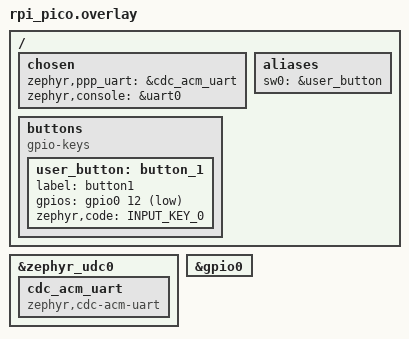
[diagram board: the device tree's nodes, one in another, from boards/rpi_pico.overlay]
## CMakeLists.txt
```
# SPDX-License-Identifier: Apache-2.0

cmake_minimum_required(VERSION 3.20.0)

find_package(Zephyr REQUIRED HINTS $ENV{ZEPHYR_BASE})
project(PanduzaHA-ng)

set(app_sources
    src/main.c
    src/app_mqtt.c
    src/panduza.c
    src/panduza_dio.c
)
target_sources(app PRIVATE ${app_sources})
```

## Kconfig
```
# Config options for mqtt_publisher sample application

# Copyright (c) 2020 Intel Corporation
# SPDX-License-Identifier: Apache-2.0

mainmenu "PanduzaHA-ng application"

config NET_SAMPLE_APP_MAX_ITERATIONS
	int "Number of times to Publish sample MQTT messages"
	default 500
	help
	  Send sample MQTT messages this many times in a MQTT connection
	  before exiting. A value of zero means that the messages are sent
	  forever.

config NET_SAMPLE_APP_MAX_CONNECTIONS
	int "Number of times to connect to the MQTT server"
	default 0
	help
	  Number of times to connect to the MQTT server. With each connection
	  send NET_SAMPLE_APP_MAX_ITERATIONS amount of MQTT sample messages.
	  A value of zero means to continue forever.

menu "Panduza configuration"

config PANDUZA_BENCH_NAME
	string "Bench Name"
	default "default"
	help
		"Change bench name that appear on the broker" 

config PANDUZA_DEVICE_NAME
	string "Device Name"
	default BOARD
	help
		"Change the device name that appear on the broker" 


endmenu

menu "Zephy Kernel"
source "Kconfig.zephyr"
endmenu
```

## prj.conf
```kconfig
CONFIG_UART_INTERRUPT_DRIVEN=y
# CONFIG_NET_IPV6 is not set
CONFIG_PINCTRL=y
CONFIG_GPIO=y
CONFIG_SERIAL=y
# CONFIG_NET_TCP_CHECKSUM is not set
CONFIG_NET_DRIVERS=y
CONFIG_CONSOLE=y
CONFIG_UART_CONSOLE=y
CONFIG_NET_PPP=y
CONFIG_PPP_CLIENT_CLIENTSERVER=y
# CONFIG_MODEM_MODULES=y
# CONFIG_MODEM_PPP=y
CONFIG_NETWORKING=y
CONFIG_NET_L2_PPP=y
CONFIG_NET_IPV4=y
CONFIG_NET_TCP=y
# CONFIG_NET_TCP_RANDOMIZED_RTO is not set
# CONFIG_NET_TCP_FAST_RETRANSMIT is not set
# CONFIG_NET_TCP_CONGESTION_AVOIDANCE is not set
# CONFIG_NET_TCP_ISN_RFC6528 is not set
# CONFIG_NET_TCP_REJECT_CONN_WITH_RST is not set
# CONFIG_NET_UDP is not set
# CONFIG_NET_LOG=y
CONFIG_MQTT_LIB=y
CONFIG_TEST_RANDOM_GENERATOR=y

CONFIG_NET_CONFIG_SETTINGS=y
CONFIG_NET_CONFIG_MY_IPV4_ADDR="192.0.1.1"
CONFIG_NET_CONFIG_PEER_IPV4_ADDR="192.0.1.2"

CONFIG_JSON_LIBRARY=y
CONFIG_GPIO_GET_CONFIG=y
CONFIG_LOG=y
CONFIG_LOG_MODE_MINIMAL=y
```

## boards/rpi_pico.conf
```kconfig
CONFIG_USB_DEVICE_STACK=y
CONFIG_USB_DEVICE_INITIALIZE_AT_BOOT=y
CONFIG_CDC_ACM_DTE_RATE_CALLBACK_SUPPORT=y
```

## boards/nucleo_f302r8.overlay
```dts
/*
 * Copyright (c) 2021 Nordic Semiconductor ASA
 * SPDX-License-Identifier: Apache-2.0
 */

/* This devicetree overlay file will be automatically picked by the Zephyr
 * build system when building the sample for the nucleo_f302r8 board. It shows
 * how the example-application can be built on sample boards already provided
 * by Zephyr.
 */

/ {
	chosen {
		zephyr,uart_pipe=&uart0;
	};
};

&gpioc {
	status = "okay";
};
```

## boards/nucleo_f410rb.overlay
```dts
/*
 * Copyright (c) 2021 Nordic Semiconductor ASA
 * SPDX-License-Identifier: Apache-2.0
 */

/ {
    chosen {
        zephyr,ppp_uart=&usart2;
        zephyr,console = &usart1;
    };

    pza_dio: panduza-dio {
        compatible = "panduza,dios";
        #gpio-cells = <2>;
        pza-gpios = <&gpioa 5 GPIO_ACTIVE_HIGH>,
                    <&gpioc 13 GPIO_ACTIVE_LOW>;
    };
};
```

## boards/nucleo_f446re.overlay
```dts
/*
 * Copyright (c) 2021 Nordic Semiconductor ASA
 * SPDX-License-Identifier: Apache-2.0
 */

/* This devicetree overlay file will be automatically picked by the Zephyr
 * build system when building the sample for the nucleo_f302r8 board. It shows
 * how the example-application can be built on sample boards already provided
 * by Zephyr.
 */

/ {
	chosen {
		zephyr,ppp_uart=&usart2;
		zephyr,console = &usart1;
	};
};

&gpioc {
	status = "okay";
};
```

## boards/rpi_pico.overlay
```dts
#include <zephyr/dt-bindings/input/input-event-codes.h>

/ {
	chosen {
		zephyr,ppp_uart=&cdc_acm_uart;
		zephyr,console = &uart0;
	};

	buttons {
		compatible = "gpio-keys";
		user_button: button_1 {
			label = "button1";
			gpios = <&gpio0 12 (GPIO_PULL_UP | GPIO_ACTIVE_LOW)>;
			zephyr,code = <INPUT_KEY_0>;
		};
	};

	aliases {
		sw0 = &user_button;
	};
};

&zephyr_udc0 {
	cdc_acm_uart: cdc_acm_uart {
		compatible = "zephyr,cdc-acm-uart";
	};
};

&gpio0 {
	status = "okay";
};
```

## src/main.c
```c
/*
 * Copyright (c) 2017 Intel Corporation
 *
 * SPDX-License-Identifier: Apache-2.0
 */

#include <zephyr/logging/log.h>
LOG_MODULE_REGISTER(panduzaHA_standalone, LOG_LEVEL_DBG);

#include <zephyr/kernel.h>

#include <zephyr/random/random.h>

#include <string.h>
#include <errno.h>

#include "config.h"
#include "panduza.h"
#include "app_mqtt.h"
#include "panduza_dio.h"

static int start_app(void)
{
	int r = 0, i = 0;

	while (!CONFIG_NET_SAMPLE_APP_MAX_CONNECTIONS ||
	       i++ < CONFIG_NET_SAMPLE_APP_MAX_CONNECTIONS) {
		r = publisher();

		if (!CONFIG_NET_SAMPLE_APP_MAX_CONNECTIONS) {
			k_sleep(K_MSEC(5000));
		}
	}

	return r;
}

#if defined(CONFIG_USERSPACE)
#define STACK_SIZE 2048

#if defined(CONFIG_NET_TC_THREAD_COOPERATIVE)
#define THREAD_PRIORITY K_PRIO_COOP(CONFIG_NUM_COOP_PRIORITIES - 1)
#else
#define THREAD_PRIORITY K_PRIO_PREEMPT(8)
#endif

K_THREAD_DEFINE(app_thread, STACK_SIZE,
		start_app, NULL, NULL, NULL,
		THREAD_PRIORITY, K_USER, -1);

static K_HEAP_DEFINE(app_mem_pool, 1024 * 2);
#endif

int main(void)
{
	pza_dio_init();

#if defined(CONFIG_MQTT_LIB_TLS)
	int rc;

	rc = tls_init();
	PRINT_RESULT("tls_init", rc);
#endif

#if defined(CONFIG_USERSPACE)
	int ret;

	struct k_mem_partition *parts[] = {
#if Z_LIBC_PARTITION_EXISTS
		&z_libc_partition,
#endif
		&app_partition
	};

	ret = k_mem_domain_init(&app_domain, ARRAY_SIZE(parts), parts);
	__ASSERT(ret == 0, "k_mem_domain_init() failed %d", ret);
	ARG_UNUSED(ret);

	k_mem_domain_add_thread(&app_domain, app_thread);
	k_thread_heap_assign(app_thread, &app_mem_pool);

	k_thread_start(app_thread);
	k_thread_join(app_thread, K_FOREVER);
#else
	exit(start_app());
#endif
	return 0;
}
```

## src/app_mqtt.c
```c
#include <zephyr/net/mqtt.h>
#include <zephyr/random/random.h>
#include <zephyr/data/json.h>
#include "panduza.h"

#include "app_mqtt.h"

#include <zephyr/logging/log.h>
LOG_MODULE_REGISTER(app_mqtt, LOG_LEVEL_DBG);

#if defined(CONFIG_USERSPACE)
#include <zephyr/app_memory/app_memdomain.h>
K_APPMEM_PARTITION_DEFINE(app_partition);
struct k_mem_domain app_domain;
#define APP_BMEM K_APP_BMEM(app_partition)
#define APP_DMEM K_APP_DMEM(app_partition)
#else
#define APP_BMEM
#define APP_DMEM
#endif

APP_BMEM app_mqtt_t app;

#if defined(CONFIG_MQTT_LIB_WEBSOCKET)
/* Making RX buffer large enough that the full IPv6 packet can fit into it */
#define MQTT_LIB_WEBSOCKET_RECV_BUF_LEN 1280

/* Websocket needs temporary buffer to store partial packets */
static APP_BMEM uint8_t temp_ws_rx_buf[MQTT_LIB_WEBSOCKET_RECV_BUF_LEN];
#endif

#if defined(CONFIG_SOCKS)
static APP_BMEM struct sockaddr socks5_proxy;
#endif

static void broker_init(struct sockaddr_storage *broker)
{
#if defined(CONFIG_NET_IPV6)
	struct sockaddr_in6 *broker6 = (struct sockaddr_in6 *)&broker;

	broker6->sin6_family = AF_INET6;
	broker6->sin6_port = htons(SERVER_PORT);
	zsock_inet_pton(AF_INET6, SERVER_ADDR, &broker6->sin6_addr);

#if defined(CONFIG_SOCKS)
	struct sockaddr_in6 *proxy6 = (struct sockaddr_in6 *)&socks5_proxy;

	proxy6->sin6_family = AF_INET6;
	proxy6->sin6_port = htons(SOCKS5_PROXY_PORT);
	zsock_inet_pton(AF_INET6, SOCKS5_PROXY_ADDR, &proxy6->sin6_addr);
#endif
#else
	struct sockaddr_in *broker4 = (struct sockaddr_in *)broker;

	broker4->sin_family = AF_INET;
	broker4->sin_port = htons(SERVER_PORT);
	zsock_inet_pton(AF_INET, SERVER_ADDR, &broker4->sin_addr);
#if defined(CONFIG_SOCKS)
	struct sockaddr_in *proxy4 = (struct sockaddr_in *)&socks5_proxy;

	proxy4->sin_family = AF_INET;
	proxy4->sin_port = htons(SOCKS5_PROXY_PORT);
	zsock_inet_pton(AF_INET, SOCKS5_PROXY_ADDR, &proxy4->sin_addr);
#endif
#endif
}

#include "panduza_dio.h"
char payload[1024];
void mqtt_evt_handler(struct mqtt_client *const client,
		      const struct mqtt_evt *evt)
{
	int err;

	switch (evt->type) {
	case MQTT_EVT_CONNACK:
		if (evt->result != 0) {
			LOG_ERR("MQTT connect failed %d", evt->result);
			break;
		}

		app.connected = true;
		LOG_INF("MQTT client connected!");
		panduza_server_publish_info();
		pza_dio_publish_all();
		break;

	case MQTT_EVT_DISCONNECT:
		LOG_INF("MQTT client disconnected %d", evt->result);

		app.connected = false;
		clear_fds();

		break;

	case MQTT_EVT_PUBACK:
		if (evt->result != 0) {
			LOG_ERR("MQTT PUBACK error %d", evt->result);
			break;
		}

		LOG_INF("PUBACK packet id: %u", evt->param.puback.message_id);

		break;

	case MQTT_EVT_PUBREC:
		if (evt->result != 0) {
			LOG_ERR("MQTT PUBREC error %d", evt->result);
			break;
		}

		LOG_INF("PUBREC packet id: %u", evt->param.pubrec.message_id);

		const struct mqtt_pubrel_param rel_param = {
			.message_id = evt->param.pubrec.message_id
		};

		err = mqtt_publish_qos2_release(client, &rel_param);
		if (err != 0) {
			LOG_ERR("Failed to send MQTT PUBREL: %d", err);
		}

		break;

	case MQTT_EVT_PUBCOMP:
		if (evt->result != 0) {
			LOG_ERR("MQTT PUBCOMP error %d", evt->result);
			break;
		}

		LOG_INF("PUBCOMP packet id: %u",
			evt->param.pubcomp.message_id);

		break;

	case MQTT_EVT_PINGRESP:
		LOG_INF("PINGRESP packet");
		// panduza_publish_info();
		panduza_server_publish_info();
		pza_dio_publish_all();
		break;

	case MQTT_EVT_PUBLISH:
		LOG_INF("PUBLISH event");
		LOG_DBG("topic=%s [%d]", evt->param.publish.message.topic.topic.utf8, evt->param.publish.message.payload.len);
		mqtt_read_publish_payload_blocking(&app.client, payload, evt->param.publish.message.payload.len);
		LOG_DBG("payload=%s", payload);
		if(strstr(evt->param.publish.message.topic.topic.utf8, "dio-controller") != NULL)
		{
			pza_dio_handle_event(evt->param.publish.message.topic.topic.utf8, payload, evt->param.publish.message.payload.len);
		}
		break;

	case MQTT_EVT_SUBACK:
		LOG_INF("SUBACK event");
		break;

	default:
		break;
	}
}

static void app_mqtt_init()
{
	mqtt_client_init(&app.client);

	broker_init(&app.broker);

	/* MQTT client configuration */
	app.client.broker = &app.broker;
	app.client.evt_cb = mqtt_evt_handler;
	app.client.client_id.utf8 = (uint8_t *)MQTT_CLIENTID;
	app.client.client_id.size = strlen(MQTT_CLIENTID);
	app.client.password = NULL;
	app.client.user_name = NULL;
	app.client.protocol_version = MQTT_VERSION_3_1_1;

	/* MQTT buffers configuration */
	app.client.rx_buf = app.rx_buffer;
	app.client.rx_buf_size = sizeof(app.rx_buffer);
	app.client.tx_buf = app.tx_buffer;
	app.client.tx_buf_size = sizeof(app.tx_buffer);

	/* MQTT transport configuration */
#if defined(CONFIG_MQTT_LIB_TLS)
#if defined(CONFIG_MQTT_LIB_WEBSOCKET)
	app.client.transport.type = MQTT_TRANSPORT_SECURE_WEBSOCKET;
#else
	app.client.transport.type = MQTT_TRANSPORT_SECURE;
#endif

	struct mqtt_sec_config *tls_config = &app.client.transport.tls.config;

	tls_config->peer_verify = TLS_PEER_VERIFY_REQUIRED;
	tls_config->cipher_list = NULL;
	tls_config->sec_tag_list = m_sec_tags;
	tls_config->sec_tag_count = ARRAY_SIZE(m_sec_tags);
#if defined(MBEDTLS_X509_CRT_PARSE_C) || defined(CONFIG_NET_SOCKETS_OFFLOAD)
	tls_config->hostname = TLS_SNI_HOSTNAME;
#else
	tls_config->hostname = NULL;
#endif

#else
#if defined(CONFIG_MQTT_LIB_WEBSOCKET)
	app.client.transport.type = MQTT_TRANSPORT_NON_SECURE_WEBSOCKET;
#else
	app.client.transport.type = MQTT_TRANSPORT_NON_SECURE;
#endif
#endif

#if defined(CONFIG_MQTT_LIB_WEBSOCKET)
	app.client.transport.websocket.config.host = SERVER_ADDR;
	app.client.transport.websocket.config.url = "/mqtt";
	app.client.transport.websocket.config.tmp_buf = temp_ws_rx_buf;
	app.client.transport.websocket.config.tmp_buf_len =
						sizeof(temp_ws_rx_buf);
	app.client.transport.websocket.timeout = 5 * MSEC_PER_SEC;
#endif

#if defined(CONFIG_SOCKS)
	mqtt_client_set_proxy(client, &socks5_proxy,
			      socks5_proxy.sa_family == AF_INET ?
			      sizeof(struct sockaddr_in) :
			      sizeof(struct sockaddr_in6));
#endif
}

#if defined(CONFIG_MQTT_LIB_TLS)

#include "test_certs.h"

#define TLS_SNI_HOSTNAME "localhost"
#define APP_CA_CERT_TAG 1
#define APP_PSK_TAG 2

static APP_DMEM sec_tag_t m_sec_tags[] = {
#if defined(MBEDTLS_X509_CRT_PARSE_C) || defined(CONFIG_NET_SOCKETS_OFFLOAD)
		APP_CA_CERT_TAG,
#endif
#if defined(MBEDTLS_KEY_EXCHANGE_SOME_PSK_ENABLED)
		APP_PSK_TAG,
#endif
};

static int tls_init(void)
{
	int err = -EINVAL;

#if defined(MBEDTLS_X509_CRT_PARSE_C) || defined(CONFIG_NET_SOCKETS_OFFLOAD)
	err = tls_credential_add(APP_CA_CERT_TAG, TLS_CREDENTIAL_CA_CERTIFICATE,
				 ca_certificate, sizeof(ca_certificate));
	if (err < 0) {
		LOG_ERR("Failed to register public certificate: %d", err);
		return err;
	}
#endif

#if defined(MBEDTLS_KEY_EXCHANGE_SOME_PSK_ENABLED)
	err = tls_credential_add(APP_PSK_TAG, TLS_CREDENTIAL_PSK,
				 client_psk, sizeof(client_psk));
	if (err < 0) {
		LOG_ERR("Failed to register PSK: %d", err);
		return err;
	}

	err = tls_credential_add(APP_PSK_TAG, TLS_CREDENTIAL_PSK_ID,
				 client_psk_id, sizeof(client_psk_id) - 1);
	if (err < 0) {
		LOG_ERR("Failed to register PSK ID: %d", err);
	}
#endif

	return err;
}

#endif /* CONFIG_MQTT_LIB_TLS */

static void prepare_fds()
{
	if (app.client.transport.type == MQTT_TRANSPORT_NON_SECURE) {
		app.fds[0].fd = app.client.transport.tcp.sock;
	}
#if defined(CONFIG_MQTT_LIB_TLS)
	else if (client->transport.type == MQTT_TRANSPORT_SECURE) {
		fds[0].fd = client->transport.tls.sock;
	}
#endif

	app.fds[0].events = ZSOCK_POLLIN;
	app.nfds = 1;
}

void clear_fds(void)
{
	app.nfds = 0;
}

int wait(int timeout)
{
	int ret = 0;

	if (app.nfds > 0) {
		ret = zsock_poll(app.fds, app.nfds, timeout);
		if (ret < 0) {
			LOG_ERR("poll error: %d", errno);
		}
	}

	return ret;
}

int publish(struct mqtt_client *client, const char* topic, const char* payload, enum mqtt_qos qos, bool retain)
{
	struct mqtt_publish_param param;
    LOG_DBG("publish to topic %s", topic);

	param.message.topic.qos = qos;
	param.message.topic.topic.utf8 = (uint8_t *)topic;
	param.message.topic.topic.size =
			strlen(param.message.topic.topic.utf8);
	param.message.payload.data = payload;
	param.message.payload.len =
			strlen(param.message.payload.data);
	param.message_id = sys_rand32_get();
	param.dup_flag = 0U;
	param.retain_flag = 0U;

	return mqtt_publish(client, &param);
}

#define RC_STR(rc) ((rc) == 0 ? "OK" : "ERROR")

#define PRINT_RESULT(func, rc) \
	LOG_INF("%s: %d <%s>", (func), rc, RC_STR(rc))

/* In this routine we block until the connected variable is 1 */
static int try_to_connect(struct mqtt_client *client)
{
	int rc, i = 0;

	while (i++ < 5 && !app.connected) {

		app_mqtt_init();

		rc = mqtt_connect(&app.client);
		if (rc != 0) {
			PRINT_RESULT("mqtt_connect", rc);
			k_sleep(K_MSEC(500));
			continue;
		}

		prepare_fds(&app.client);

		if (wait(100)) {
			mqtt_input(&app.client);
		}

		if (!app.connected) {
			mqtt_abort(&app.client);
		}
	}

	if (app.connected) {
		struct mqtt_topic topics[] = {
		{
			.topic = {.utf8 = "pza",
				.size = strlen("pza")},
			.qos = MQTT_QOS_0_AT_MOST_ONCE,
		}};
		const struct mqtt_subscription_list sub_list = {
			.list = topics,
			.list_count = ARRAY_SIZE(topics),
			.message_id = 1u,
		};
		int ret = mqtt_subscribe(&app.client, &sub_list);
		if (ret != 0) {
			LOG_ERR("Failed to subscribe to topics: %d", ret);
		}
		pza_dio_connect();
		return 0;
	}

	return -EINVAL;
}

static int process_mqtt_and_sleep(struct mqtt_client *client, int timeout)
{
	int64_t remaining = timeout;
	int64_t start_time = k_uptime_get();
	int rc;

	while (remaining > 0 && app.connected) {
		if (wait(remaining)) {
			rc = mqtt_input(client);
			if (rc != 0) {
				PRINT_RESULT("mqtt_input", rc);
				return rc;
			}
		}

		rc = mqtt_live(client);
		if (rc != 0 && rc != -EAGAIN) {
			PRINT_RESULT("mqtt_live", rc);
			return rc;
		} else if (rc == 0) {
			rc = mqtt_input(client);
			if (rc != 0) {
				PRINT_RESULT("mqtt_input", rc);
				return rc;
			}
		}

		remaining = timeout + start_time - k_uptime_get();
	}

	return 0;
}

#define SUCCESS_OR_EXIT(rc) { if (rc != 0) { return 1; } }
#define SUCCESS_OR_BREAK(rc) { if (rc != 0) { break; } }

int publisher(void)
{
	int i, rc, r = 0;

	LOG_INF("attempting to connect: ");
	rc = try_to_connect(&app.client);
	PRINT_RESULT("try_to_connect", rc);
	SUCCESS_OR_EXIT(rc);

	i = 0;
	while (app.connected) {
		rc = process_mqtt_and_sleep(&app.client, 1);
		SUCCESS_OR_BREAK(rc);
	}

	rc = mqtt_disconnect(&app.client);
	PRINT_RESULT("mqtt_disconnect", rc);

	LOG_INF("Bye!");

	return r;
}
```

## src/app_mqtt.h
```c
#ifndef APP_MQTT_H
#define APP_MQTT_H
#pragma once

#include <zephyr/net/mqtt.h>
#include <zephyr/net/socket.h>
#include "config.h"

typedef struct app_mqtt
{
	/* Buffers for MQTT client. */
	uint8_t rx_buffer[APP_MQTT_BUFFER_SIZE];
	uint8_t tx_buffer[APP_MQTT_BUFFER_SIZE];
	/* The mqtt client struct */
	struct mqtt_client client;
	/* MQTT Broker details. */
	struct sockaddr_storage broker;
	struct zsock_pollfd fds[1];
	int nfds;
	bool connected;
} app_mqtt_t;

int publish(struct mqtt_client *client, const char* topic, const char* payload, enum mqtt_qos qos, bool retain);
int publisher(void);
#endif
```

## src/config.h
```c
/*
 * Copyright (c) 2017 Intel Corporation
 *
 * SPDX-License-Identifier: Apache-2.0
 */

#ifndef __CONFIG_H__
#define __CONFIG_H__

#ifdef CONFIG_NET_CONFIG_SETTINGS
#ifdef CONFIG_NET_IPV6
#define ZEPHYR_ADDR		CONFIG_NET_CONFIG_MY_IPV6_ADDR
#define SERVER_ADDR		CONFIG_NET_CONFIG_PEER_IPV6_ADDR
#else
#define ZEPHYR_ADDR		CONFIG_NET_CONFIG_MY_IPV4_ADDR
#define SERVER_ADDR		CONFIG_NET_CONFIG_PEER_IPV4_ADDR
#endif
#else
#ifdef CONFIG_NET_IPV6
#define ZEPHYR_ADDR		"2001:db8::1"
#define SERVER_ADDR		"2001:db8::2"
#else
#define ZEPHYR_ADDR		"192.0.1.1"
#define SERVER_ADDR		"192.0.1.2"
#endif
#endif

#if defined(CONFIG_SOCKS)
#define SOCKS5_PROXY_ADDR	SERVER_ADDR
#define SOCKS5_PROXY_PORT	1080
#endif

#ifdef CONFIG_MQTT_LIB_TLS
#ifdef CONFIG_MQTT_LIB_WEBSOCKET
#define SERVER_PORT		9001
#else
#define SERVER_PORT		8883
#endif /* CONFIG_MQTT_LIB_WEBSOCKET */
#else
#ifdef CONFIG_MQTT_LIB_WEBSOCKET
#define SERVER_PORT		9001
#else
#define SERVER_PORT		1883
#endif /* CONFIG_MQTT_LIB_WEBSOCKET */
#endif

#define APP_CONNECT_TIMEOUT_MS	2000
#define APP_SLEEP_MSECS		500

#define APP_CONNECT_TRIES	10

#define APP_MQTT_BUFFER_SIZE	128

#define MQTT_CLIENTID		"PanduzaHA-standalone on " CONFIG_BOARD

#endif
```

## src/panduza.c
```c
#include "panduza.h"
#include "app_mqtt.h"

#define PANDUZA_ITF_DIO_TYPE "dio-controller"
#define PANDUZA_ITF_DIO_VERSION "1.0.0"
#define PANDUZA_TIF_DIO_NUMBER_OF_IO "3"
#define PANDUZA_ITF_DIO_INFO "{\"info\":{\"type\": \""PANDUZA_ITF_DIO_TYPE"\",\"version\":\""PANDUZA_ITF_DIO_VERSION"\",\"state\":\"run\",\"number_of_interfaces\":"PANDUZA_TIF_DIO_NUMBER_OF_IO"}}"
#define PANDUZA_ITF_DIO_IDENTITY "{\"identity\":{\"family\": \"DIO\",\"model\":\"generic\",\"manufacturer\":\"Panduza\"}}"

#define PANDUZA_DIO_TYPE "dio"
#define PANDUZA_DIO_VERSION "1.0.0"
#define PANDUZA_DIO_INFO "{\"info\":{\"type\": \""PANDUZA_DIO_TYPE"\",\"version\":\""PANDUZA_DIO_VERSION"\",\"state\":\"run\"}}"

extern app_mqtt_t app;

void panduza_publish_identity()
{
    // publish(&app.client, PANDUZA_TOPIC_BASE"/io/device/atts/identity", PANDUZA_ITF_DIO_IDENTITY, MQTT_QOS_0_AT_MOST_ONCE, true);
}

void panduza_server_publish_info()
{
    publish(&app.client, "pza/server/"CONFIG_PANDUZA_DEVICE_NAME"/device/atts/info", PANDUZA_ITF_DIO_INFO, MQTT_QOS_0_AT_MOST_ONCE, true);
    publish(&app.client, "pza/server/"CONFIG_PANDUZA_DEVICE_NAME"/device/atts/identity", PANDUZA_ITF_DIO_IDENTITY, MQTT_QOS_0_AT_MOST_ONCE, true);
}
```

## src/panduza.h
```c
#ifndef PANDUZA_H
#define PANDUZA_H
#pragma once

#include "config.h"
#include <stdbool.h>
#define PANDUZA_TOPIC_BASE "pza/"CONFIG_PANDUZA_BENCH_NAME"/"CONFIG_PANDUZA_DEVICE_NAME"-dio-controller"

void panduza_publish_info(void);
void panduza_publish_identity();
void panduza_push_dio_direction(int interface, bool direction, bool pull);
void panduza_push_dio_update(int interface, bool state, bool active_low);
#endif
```

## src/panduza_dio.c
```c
#include "panduza_dio.h"

#include <zephyr/logging/log.h>
LOG_MODULE_REGISTER(panduza_dio, LOG_LEVEL_DBG);

#include <zephyr/data/json.h>
#include "app_mqtt.h"

#define PZA_DIO_NODE DT_NODELABEL(pza_dio) // Panduza DIO device tree node
// macro to instanciate a DIO
#define PZA_DIO_DECLARE(node_id, prop, idx)                                 \
    {                                                                       \
        .bank = DT_NODE_CHILD_IDX(DT_GPIO_CTLR_BY_IDX(node_id, prop, idx)), \
        .gpio = GPIO_DT_SPEC_GET_BY_IDX(node_id, prop, idx)                 \
    }
// Panduza DIO instances array
dio_t pzaDIO[] = {DT_FOREACH_PROP_ELEM_SEP(PZA_DIO_NODE, pza_gpios, PZA_DIO_DECLARE, (, ))};
static char cmds_strs[ARRAY_SIZE(pzaDIO)][128];      // array of strings to store the path to each dio CMDS
static struct mqtt_topic topics[ARRAY_SIZE(pzaDIO)]; // topic array to subscribe to DIOs CMDS
// MQTT subscription list struct
static const struct mqtt_subscription_list sub_list = {
    .list = topics,
    .list_count = ARRAY_SIZE(topics),
    .message_id = 1u,
};
// gpio callback struct
static struct gpio_callback dio_cb_data;

extern app_mqtt_t app;

#define PANDUZA_TOPIC_BASE "pza/" CONFIG_PANDUZA_BENCH_NAME "/" CONFIG_PANDUZA_DEVICE_NAME "-dio-controller"

static const struct json_obj_descr dio_direction_json_desc[] = {
    JSON_OBJ_DESCR_PRIM(dio_direction_t, value, JSON_TOK_STRING),
    JSON_OBJ_DESCR_PRIM(dio_direction_t, pull, JSON_TOK_STRING),
    JSON_OBJ_DESCR_PRIM(dio_direction_t, polling_cycle, JSON_TOK_NUMBER),
};
static const struct json_obj_descr dio_direction_json[] = {
    JSON_OBJ_DESCR_OBJECT(dio_t, direction, dio_direction_json_desc)};

static const struct json_obj_descr dio_state_json_desc[] = {
    JSON_OBJ_DESCR_PRIM(dio_state_t, active, JSON_TOK_TRUE),
    JSON_OBJ_DESCR_PRIM(dio_state_t, active_low, JSON_TOK_TRUE),
    JSON_OBJ_DESCR_PRIM(dio_state_t, polling_cycle, JSON_TOK_NUMBER),
};
static const struct json_obj_descr dio_state_json[] = {
    JSON_OBJ_DESCR_OBJECT(dio_t, state, dio_state_json_desc)};

static unsigned char json_encoded_buf[1024];
static char topic[64];

static inline void insert_dio_id(char *str, dio_t *dio, uint8_t offset)
{
    str[offset] = 'A' + dio->bank;
    str[offset + 1] = '0' + dio->gpio.pin / 10;
    str[offset + 2] = '0' + dio->gpio.pin % 10;
}

void panduza_dio_publish_direction(dio_t *dio)
{
    gpio_flags_t flags = 0;
    gpio_pin_get_config_dt(&dio->gpio, &flags);

    LOG_DBG("dio_%c%d flags=%x", dio->bank+'A', dio->gpio.pin, flags);

    dio->direction.value = (flags & GPIO_INPUT) ? "in" : "out";
    dio->direction.pull = (flags & GPIO_PULL_UP) ? "up" : "down";
    dio->direction.polling_cycle = 1;

    int status = json_obj_encode_buf(dio_direction_json, ARRAY_SIZE(dio_direction_json),
                                     dio, json_encoded_buf, sizeof(json_encoded_buf));
    LOG_DBG("json encoding status: %d", status);

    strcpy(topic, PANDUZA_TOPIC_BASE "/dio_xxx/atts/direction");
    insert_dio_id(topic, dio, strlen(topic) - 18);
    publish(&app.client, topic, json_encoded_buf, MQTT_QOS_0_AT_MOST_ONCE, true);
}

void panduza_dio_publish_state(dio_t *dio)
{
    gpio_flags_t flags = 0;
    gpio_pin_get_config_dt(&dio->gpio, &flags);

    dio->state.active = gpio_pin_get_dt(&dio->gpio);
    dio->state.active_low = flags & GPIO_OUTPUT_INIT_LOW;
    dio->state.polling_cycle = 1;

    int status = json_obj_encode_buf(dio_state_json, ARRAY_SIZE(dio_state_json),
                                     dio, json_encoded_buf, sizeof(json_encoded_buf));
    LOG_DBG("json encoding status: %d", status);

    strcpy(topic, PANDUZA_TOPIC_BASE "/dio_xxx/atts/state");
    insert_dio_id(topic, dio, strlen(topic) - 14);
    publish(&app.client, topic, json_encoded_buf, MQTT_QOS_0_AT_MOST_ONCE, false);
}

void panduza_dio_publish_info(dio_t *dio)
{
    strcpy(topic, PANDUZA_TOPIC_BASE "/dio_xxx/atts/info");
    insert_dio_id(topic, dio, strlen(topic) - 13);
    publish(&app.client, topic, PANDUZA_DIO_INFO, MQTT_QOS_0_AT_MOST_ONCE, true);
}

void dio_interrupt(const struct device *dev, struct gpio_callback *cb,
                   uint32_t pins)
{
    for (int i = 0; i < 32; i++)
    {
        if (pins & BIT(i))
        {
            gpio_flags_t flags = 0;
            gpio_pin_get_config(dev, i, &flags);
            for (uint8_t j = 0; j < ARRAY_SIZE(pzaDIO); j++)
            {
                if (pzaDIO[j].gpio.pin == i && pzaDIO[j].gpio.port == dev)
                {
                    panduza_dio_publish_state(&pzaDIO[j]);
                }
            }

            return;
        }
    }
}

void pza_dio_init()
{
    LOG_INF("ARRAY_SIZE(pzaDIO)=%d", ARRAY_SIZE(pzaDIO));

    for (uint8_t i = 0; i < ARRAY_SIZE(pzaDIO); i++)
    {
        if (!gpio_is_ready_dt(&pzaDIO[i]))
        {
            LOG_ERR("Error: pzaDIO[%d] device %s is not ready\n",
                    i, pzaDIO[i].gpio.port->name);
            return;
        }

        if (gpio_pin_configure_dt(&pzaDIO[i], GPIO_INPUT) != 0)
        {
            LOG_ERR("Error: failed to configure %s pin %d\n", pzaDIO[i].gpio.port->name, pzaDIO[i].gpio.pin);
            return;
        }

        if (gpio_pin_interrupt_configure_dt(&pzaDIO[i], GPIO_INT_EDGE_BOTH) != 0)
        {
            LOG_ERR("Error %d: failed to configure interrupt on %s pin %d\n", pzaDIO[i].gpio.port->name, pzaDIO[i].gpio.pin);
            return;
        }

        gpio_init_callback(&dio_cb_data, dio_interrupt, BIT(pzaDIO[i].gpio.pin));
        gpio_add_callback(pzaDIO[i].gpio.port, &dio_cb_data);

        strncpy(cmds_strs[i], PANDUZA_TOPIC_BASE "/dio_xxx/cmds/#", sizeof(PANDUZA_TOPIC_BASE "/dio_xxx/cmds/#"));
        insert_dio_id(cmds_strs[i], &pzaDIO[i], strlen(cmds_strs[i]) - 10);

        LOG_DBG("adding sub to %s", cmds_strs[i]);

        topics[i].topic.utf8 = cmds_strs[i];
        topics[i].topic.size = strlen(cmds_strs[i]);
        topics[i].qos = MQTT_QOS_0_AT_MOST_ONCE;
    }
}

void pza_dio_publish_all()
{
    for (uint8_t j = 0; j < ARRAY_SIZE(pzaDIO); j++)
    {
        panduza_dio_publish_info(&pzaDIO[j]);
        panduza_dio_publish_state(&pzaDIO[j]);
        panduza_dio_publish_direction(&pzaDIO[j]);
    }
}

void pza_dio_connect()
{
    int ret = mqtt_subscribe(&app.client, &sub_list);
    if (ret != 0)
    {
        LOG_ERR("Failed to subscribe to topics: %d", ret);
    }
}

void pza_dio_handle_event(char *topic, char *payload, uint32_t payload_length)
{
    //detect dio
    char *dio_identifier = topic + sizeof(PANDUZA_TOPIC_BASE "/dio_") - 1;
    char bank = *dio_identifier - 'A';
    int pin = (*(dio_identifier+1) - '0')*10 + (*(dio_identifier+2) - '0');
    LOG_DBG("parsed topic: bank=%c pin=%d", bank+'A', pin);
    dio_t *dio = NULL;
    for (uint8_t j = 0; j < ARRAY_SIZE(pzaDIO); j++)
    {
        if (pzaDIO[j].gpio.pin == pin && pzaDIO[j].bank == bank)
        {
            dio = &pzaDIO[j];
        }
    }
    if(dio == NULL)
    {
        LOG_ERR("dio not found");
        return;
    }
    char *sub_topic = topic + sizeof(PANDUZA_TOPIC_BASE "/dio_xxx/cmds/") - 1;
    LOG_DBG("parsed sub topic is %s", sub_topic);
    if(*sub_topic == 'd')
    {
        LOG_DBG("guess for direction");
        int ret = json_obj_parse(payload, payload_length, dio_direction_json, ARRAY_SIZE(dio_direction_json), dio);
        LOG_DBG("ret=%d", ret);
        LOG_DBG("direction.value=%s", dio->direction.value);
        LOG_DBG("direction.pull=%s", dio->direction.pull);
        LOG_DBG("direction.polling_cycle=%d", dio->direction.polling_cycle);
        gpio_flags_t flags = 0;
        if(*dio->direction.value=='o')
        {
            flags = GPIO_OUTPUT;
        }
        else
        {
            flags = GPIO_INPUT;
        }
        gpio_pin_configure_dt(&dio->gpio, flags);
        // gpio_flags_t it;
        // if(!(flags & GPIO_INPUT))
        // {
        //     LOG_DBG("disable interrupt");
        //     it = GPIO_INT_DISABLE;
        // }
        // else
        // {
        //     LOG_DBG("enable interrupt");
        //     it = GPIO_INT_EDGE_BOTH;
        // }
        // gpio_pin_interrupt_configure_dt(&dio->gpio, it);
        panduza_dio_publish_direction(dio);
    }
    else if(*sub_topic == 's')
    {
        LOG_DBG("guess for state");
        int ret = json_obj_parse(payload, payload_length, dio_state_json, ARRAY_SIZE(dio_state_json), dio);
        LOG_DBG("ret=%d", ret);
        LOG_DBG("state.active=%d", dio->state.active);
        LOG_DBG("state.active_low=%d", dio->state.active_low);
        LOG_DBG("state.polling_cycle=%d", dio->state.polling_cycle);
        gpio_pin_set_dt(&dio->gpio, dio->state.active);
        panduza_dio_publish_state(dio);
    }
}
```

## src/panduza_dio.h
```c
#ifndef PANDUZA_DIO_H
#define PANDUZA_DIO_H
#pragma once

#include <zephyr/drivers/gpio.h>

#define PANDUZA_DIO_TYPE "dio"
#define PANDUZA_DIO_VERSION "1.0.0"
#define PANDUZA_DIO_INFO "{\"info\":{\"type\": \""PANDUZA_DIO_TYPE"\",\"version\":\""PANDUZA_DIO_VERSION"\",\"state\":\"run\"}}"

typedef struct dio_state {
    bool active;
    bool active_low;
    int polling_cycle;
} dio_state_t;

typedef struct dio_direction {
    char* value;
    char* pull;
    int polling_cycle;
} dio_direction_t;

typedef struct panduza_dio
{
    struct gpio_dt_spec gpio;
    char bank;
    dio_state_t state;
    dio_direction_t direction;
} dio_t;

void panduza_dio_publish_direction(dio_t *dio);
void panduza_dio_publish_state(dio_t *dio);
void panduza_dio_publish_info(dio_t *dio);

void pza_dio_init();
void pza_dio_publish_all();
void pza_dio_connect();
void pza_dio_handle_event(char *topic, char *payload, uint32_t payload_length);
#endif
```
